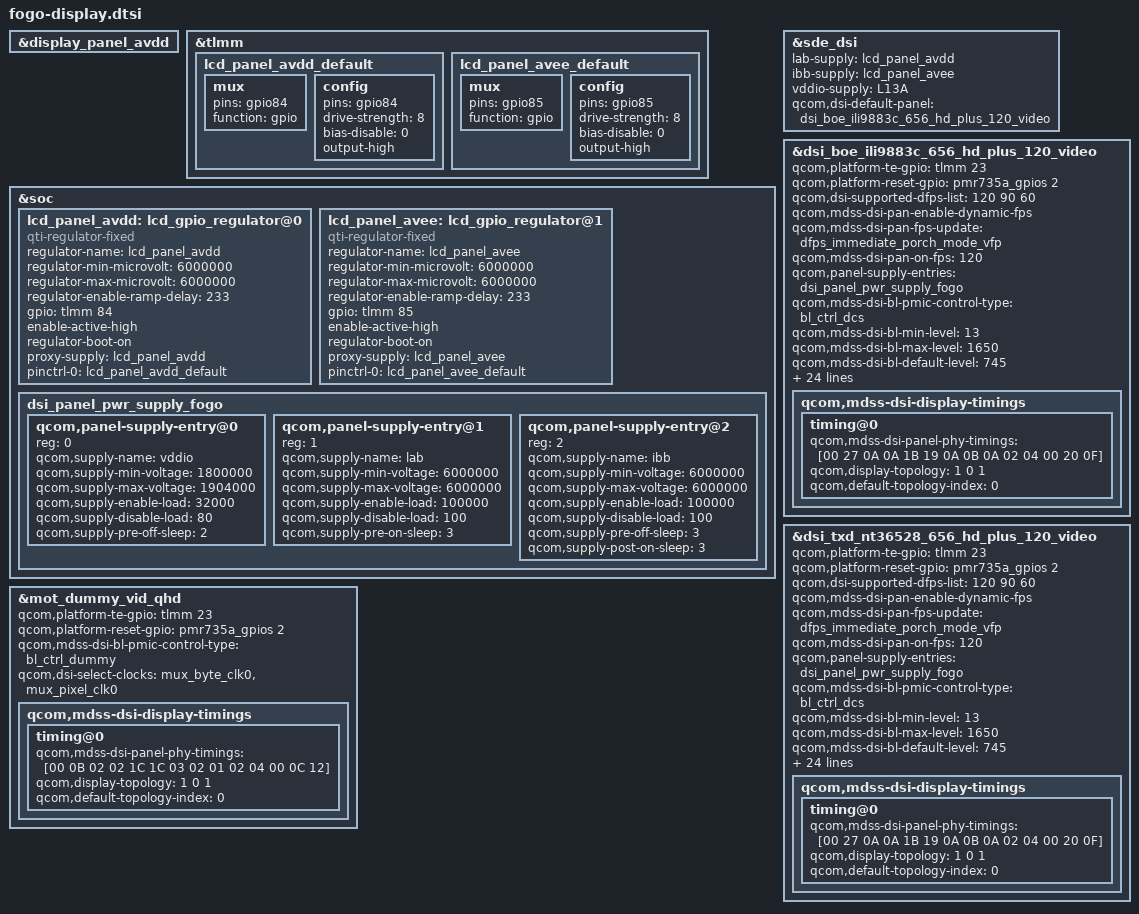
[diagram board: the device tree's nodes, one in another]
#include "dsi-panel-mot-dummy-qhd-video.dtsi"
#include "dsi-panel-mot-boe-ili9883c-656-720x1612-video.dtsi"
#include "dsi-panel-mot-txd-nt36528-656-720x1612-video.dtsi"

&display_panel_avdd {
	/delete-property/ gpio;
	/delete-property/ pinctrl-0;
};

&tlmm {
	lcd_panel_avdd_default: lcd_panel_avdd_default {
		mux {
			pins = "gpio84";
			function = "gpio";
		};

		config {
			pins = "gpio84";
			drive-strength = <8>;
			bias-disable = <0>;
			output-high;
		};
	};

	lcd_panel_avee_default: lcd_panel_avee_default {
		mux {
			pins = "gpio85";
			function = "gpio";
		};

		config {
			pins = "gpio85";
			drive-strength = <8>;
			bias-disable = <0>;
			output-high;
		};
	};
};

&soc {
	lcd_panel_avdd: lcd_gpio_regulator@0 {
		compatible = "qti-regulator-fixed";
		regulator-name = "lcd_panel_avdd";
		regulator-min-microvolt = <6000000>;
		regulator-max-microvolt = <6000000>;
		regulator-enable-ramp-delay = <233>;
		gpio = <&tlmm 84 0>;
		enable-active-high;
		regulator-boot-on;
		proxy-supply = <&lcd_panel_avdd>;
		pinctrl-names = "default";
		pinctrl-0 = <&lcd_panel_avdd_default>;
	};

	lcd_panel_avee: lcd_gpio_regulator@1 {
		compatible = "qti-regulator-fixed";
		regulator-name = "lcd_panel_avee";
		regulator-min-microvolt = <6000000>;
		regulator-max-microvolt = <6000000>;
		regulator-enable-ramp-delay = <233>;
		gpio = <&tlmm 85 0>;
		enable-active-high;
		regulator-boot-on;
		proxy-supply = <&lcd_panel_avee>;
		pinctrl-names = "default";
		pinctrl-0 = <&lcd_panel_avee_default>;
	};

	dsi_panel_pwr_supply_fogo: dsi_panel_pwr_supply_fogo{
		#address-cells = <1>;
		#size-cells = <0>;

		qcom,panel-supply-entry@0 {
			reg = <0>;
			qcom,supply-name = "vddio";
			qcom,supply-min-voltage = <1800000>;
			qcom,supply-max-voltage = <1904000>;
			qcom,supply-enable-load = <32000>;
			qcom,supply-disable-load = <80>;
			qcom,supply-pre-off-sleep = <2>;
		};

		qcom,panel-supply-entry@1 {
			reg = <1>;
			qcom,supply-name = "lab";
			qcom,supply-min-voltage = <6000000>;
			qcom,supply-max-voltage = <6000000>;
			qcom,supply-enable-load = <100000>;
			qcom,supply-disable-load = <100>;
			qcom,supply-pre-on-sleep = <3>;
		};

		qcom,panel-supply-entry@2 {
			reg = <2>;
			qcom,supply-name = "ibb";
			qcom,supply-min-voltage = <6000000>;
			qcom,supply-max-voltage = <6000000>;
			qcom,supply-enable-load = <100000>;
			qcom,supply-disable-load = <100>;
			qcom,supply-pre-off-sleep = <3>;
			qcom,supply-post-on-sleep = <3>;
		};

	};
};

&sde_dsi {
	/delete-property/ lab-supply;
	/delete-property/ ibb-supply;
	/delete-property/ vddio-supply;
	/delete-property/ qcom,dsi-default-panel;
	/delete-property/ avdd-supply;

	lab-supply = <&lcd_panel_avdd>;
	ibb-supply = <&lcd_panel_avee>;
	vddio-supply = <&L13A>;

	qcom,dsi-default-panel = <&dsi_boe_ili9883c_656_hd_plus_120_video>;
};

&dsi_boe_ili9883c_656_hd_plus_120_video{
	qcom,platform-te-gpio = <&tlmm 23 0>;
	qcom,platform-reset-gpio = <&pmr735a_gpios 2 0>;

	qcom,dsi-supported-dfps-list = <120 90 60>;
	qcom,mdss-dsi-pan-enable-dynamic-fps;
	qcom,mdss-dsi-pan-fps-update = "dfps_immediate_porch_mode_vfp";
	/*qcom,mdss-dsi-pan-dfps-send-command;*/
	qcom,mdss-dsi-pan-on-fps = <120>;

	qcom,panel-supply-entries = <&dsi_panel_pwr_supply_fogo>;

	qcom,mdss-dsi-bl-pmic-control-type = "bl_ctrl_dcs";
	qcom,mdss-dsi-bl-min-level = <13>;
	qcom,mdss-dsi-bl-max-level = <1650>;
	qcom,mdss-dsi-bl-default-level = <745>;
	qcom,mdss-brightness-max-level = <1650>;
	qcom,bklt-dcs-2bytes-enabled;

	qcom,mdss-dsi-no-panel-on-read-support;

/*	qcom,mdss-dsi-panel-hdr-enable;
	qcom,mdss-dsi-panel-hdr-color-primaries = <14950 15750 34000
					16000 13000 35500 7000 2500>;
	qcom,mdss-dsi-panel-peak-brightness = <5000000>;
	qcom,mdss-dsi-panel-blackness-level = <100>;
*/
	qcom,esd-check-enabled;
	qcom,mdss-dsi-panel-status-check-mode = "reg_read";
	qcom,mdss-dsi-panel-status-command = [06 01 00 01 00 00 01 0A];
	qcom,mdss-dsi-panel-status-command-state = "dsi_lp_mode";
	qcom,mdss-dsi-panel-status-value = <0x9C>;
	qcom,mdss-dsi-panel-status-read-length = <1>;

	qcom,mdss-dsi-panel-hbm-is-51cmd;
	qcom,mdss-dsi-hbm-type = "lcd-dcs-wled";
	qcom,mdss-dsi-hbm-on-command = [39 01 00 00 00 00 03 51 07 FF];
	qcom,mdss-dsi-hbm-on-command-state =  "dsi_lp_mode";
	qcom,mdss-dsi-hbm-off-command = [39 01 00 00 00 00 03 51 06 66];
	qcom,mdss-dsi-hbm-off-command-state =  "dsi_lp_mode";

	qcom,dsi-select-clocks = "mux_byte_clk0", "mux_pixel_clk0";

	qcom,mdss-dsi-display-timings {
		timing@0 {
			qcom,mdss-dsi-panel-phy-timings = [00 27 0A 0A 1B 19 0A
				0B 0A 02 04 00 20 0F];

			qcom,display-topology = <1 0 1>;
			qcom,default-topology-index = <0>;
		};
	};
};
&dsi_txd_nt36528_656_hd_plus_120_video{
	qcom,platform-te-gpio = <&tlmm 23 0>;
	qcom,platform-reset-gpio = <&pmr735a_gpios 2 0>;

	qcom,dsi-supported-dfps-list = <120 90 60>;
	qcom,mdss-dsi-pan-enable-dynamic-fps;
	qcom,mdss-dsi-pan-fps-update = "dfps_immediate_porch_mode_vfp";
	/*qcom,mdss-dsi-pan-dfps-send-command;*/
	qcom,mdss-dsi-pan-on-fps = <120>;

	qcom,panel-supply-entries = <&dsi_panel_pwr_supply_fogo>;

	qcom,mdss-dsi-bl-pmic-control-type = "bl_ctrl_dcs";
	qcom,mdss-dsi-bl-min-level = <13>;
	qcom,mdss-dsi-bl-max-level = <1650>;
	qcom,mdss-dsi-bl-default-level = <745>;
	qcom,mdss-brightness-max-level = <1650>;
	qcom,bklt-dcs-2bytes-enabled;

	qcom,mdss-dsi-no-panel-on-read-support;

/*	qcom,mdss-dsi-panel-hdr-enable;
	qcom,mdss-dsi-panel-hdr-color-primaries = <14950 15750 34000
					16000 13000 35500 7000 2500>;
	qcom,mdss-dsi-panel-peak-brightness = <5000000>;
	qcom,mdss-dsi-panel-blackness-level = <100>;
*/
	qcom,esd-check-enabled;
	qcom,mdss-dsi-panel-status-check-mode = "reg_read";
	qcom,mdss-dsi-panel-status-command = [06 01 00 01 00 00 01 0A];
	qcom,mdss-dsi-panel-status-command-state = "dsi_lp_mode";
	qcom,mdss-dsi-panel-status-value = <0x9C>;
	qcom,mdss-dsi-panel-status-read-length = <1>;

	qcom,mdss-dsi-panel-hbm-is-51cmd;
	qcom,mdss-dsi-hbm-type = "lcd-dcs-wled";
	qcom,mdss-dsi-hbm-on-command = [39 01 00 00 00 00 03 51 07 FF];
	qcom,mdss-dsi-hbm-on-command-state =  "dsi_lp_mode";
	qcom,mdss-dsi-hbm-off-command = [39 01 00 00 00 00 03 51 06 66];
	qcom,mdss-dsi-hbm-off-command-state =  "dsi_lp_mode";

	qcom,dsi-select-clocks = "mux_byte_clk0", "mux_pixel_clk0";

	qcom,mdss-dsi-display-timings {
		timing@0 {
			qcom,mdss-dsi-panel-phy-timings = [00 27 0A 0A 1B 19 0A
				0B 0A 02 04 00 20 0F];

			qcom,display-topology = <1 0 1>;
			qcom,default-topology-index = <0>;
		};
	};
};

&mot_dummy_vid_qhd {
	qcom,platform-te-gpio = <&tlmm 23 0>;
	qcom,platform-reset-gpio = <&pmr735a_gpios 2 0>;

	qcom,mdss-dsi-bl-pmic-control-type = "bl_ctrl_dummy";

	qcom,dsi-select-clocks = "mux_byte_clk0", "mux_pixel_clk0";

	qcom,mdss-dsi-display-timings {
		timing@0 {
			qcom,mdss-dsi-panel-phy-timings = [00 0B 02 02 1C 1C 03
							02 01 02 04 00 0C 12];
			qcom,display-topology = <1 0 1>;
			qcom,default-topology-index = <0>;
		};
	};
};
